# AS32x601 register map
File version: 1.0
CPU: RISC-V, little endian
Registers are 32-bit, read-write, reset 0x0 unless marked. A register's access mark holds for its fields unless they carry their own. Offsets are from the block's base; [hi:lo] are bit positions; {n}, {i} and the like mark numbered series.

## RTC — Real-Time Clock
Base 0x30101000
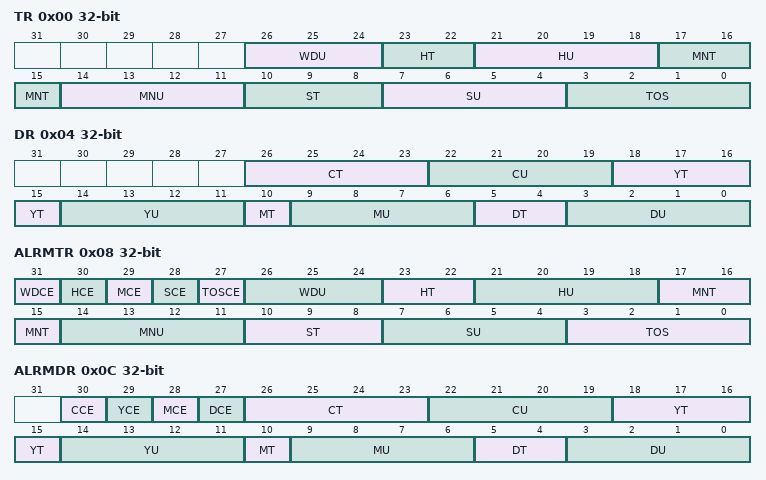
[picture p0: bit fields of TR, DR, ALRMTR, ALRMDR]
0x00 TR — RTC time register
  [26:24] WDU — Week day units [2:0]
  [23:22] HT — Hour tens [1:0]
  [21:18] HU — Hour units [3:0]
  [17:15] MNT — Minute tens [2:0]
  [14:11] MNU — Minute units [3:0]
  [10:8] ST — Second tens [2:0]
  [7:4] SU — Second units [3:0]
  [3:0] TOS — Tenth of a second [3:0]
0x04 DR — RTC date register
  [26:23] CT — Century tens [3:0]
  [22:19] CU — Century units [3:0]
  [18:15] YT — Year tens [3:0]
  [14:11] YU — Year units [3:0]
  [10] MT — Month tens
  [9:6] MU — Month units [3:0]
  [5:4] DT — Date tens [1:0]
  [3:0] DU — Date units [3:0]
0x08 ALRMTR — RTC alarm time register
  [31] WDCE — Week day comparison enable
  [30] HCE — Hour comparison enable
  [29] MCE — Minute comparison enable
  [28] SCE — Second comparison enable
  [27] TOSCE — One tenth of a second comparison enable
  [26:24] WDU — Week day units [2:0]
  [23:22] HT — Hour tens [1:0]
  [21:18] HU — Hour units [3:0]
  [17:15] MNT — Minute tens [2:0]
  [14:11] MNU — Minute units [3:0]
  [10:8] ST — Second tens [2:0]
  [7:4] SU — Second units [3:0]
  [3:0] TOS — Tenth of a second [3:0]
0x0C ALRMDR — RTC alarm date register
  [30] CCE — Century comparison enable
  [29] YCE — Year comparison enable
  [28] MCE — Month comparison enable
  [27] DCE — Date comparison enable
  [26:23] CT — Century tens [3:0]
  [22:19] CU — Century units [3:0]
  [18:15] YT — Year tens [3:0]
  [14:11] YU — Year units [3:0]
  [10] MT — Month tens
  [9:6] MU — Month units [3:0]
  [5:4] DT — Date tens [1:0]
  [3:0] DU — Date units [3:0]
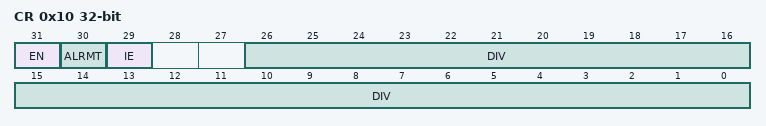
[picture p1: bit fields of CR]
0x10 CR — RTC control register
  [31] EN — RTC enable
  [30] ALRMT — Alarm trigger
  [29] IE — Interrupt enable
  [26:0] DIV — RTC clock divider [26:0]
0x14 WUCR — RTC wake-up control register
  [0] WUTE — Wakeup timer enable

## DAC0 — Digital-to-Analog Converter 0
Base 0x41003000
Same registers: DAC1 0x42002000
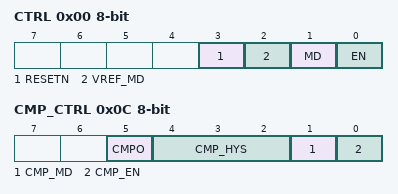
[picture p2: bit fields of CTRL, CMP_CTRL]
0x00 CTRL 8-bit — DAC Control Register
  [3] RESETN — DAC reset
  [2] VREF_MD — DAC VREF mode
  [1] MD — DAC mode
  [0] EN — DAC enable
0x04 DOUT 8-bit — DAC Data Register
  [7:0] DOUT — DAC output data [7:0]
0x08 CLK_DIV 8-bit — DAC Clock Division Register
  [7:0] CLK_DIV_NU — Clock division numerator [7:0]
0x0C CMP_CTRL 8-bit — DAC Comparator Control Register
  [5] CMPO — DAC comparator output
  [4:2] CMP_HYS — DAC comparator hysteresis [2:0]
  [1] CMP_MD — DAC comparator mode
  [0] CMP_EN — DAC comparator enable

## PKA — Public Key Accelerator
Base 0x41140000
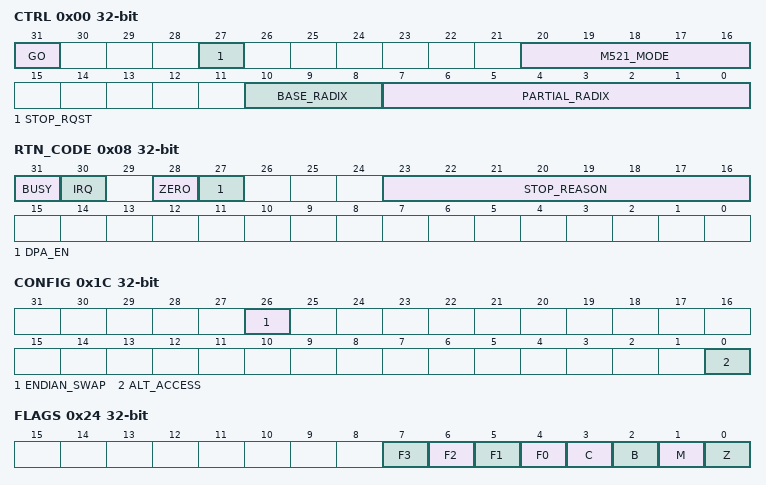
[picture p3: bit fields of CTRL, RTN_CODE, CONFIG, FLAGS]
0x00 CTRL — PKA Control Register
  [31] GO — Starts the PKA execution
  [27] STOP_RQST — Requests PKA to halt at the next instruction boundary
  [20:16] M521_MODE — Sets operating to Mersenne M-521
  [10:8] BASE_RADIX — Sets the size of the base operand size (radix)
  [7:0] PARTIAL_RADIX — Selects a partial field from within the base radix
0x04 ENTRY_PNT — PKA Program Entry Point Register
  [11:0] ADDR — Program entry point
0x08 RTN_CODE ro — PKA Return Code Register
  [31] BUSY — Indicates that the PKA is actively executing a program
  [30] IRQ — Indicates when the PKA has completed its task
  [28] ZERO — Indicates the state of the zero flag in the sequencer
  [27] DPA_EN — Indicates that the core is capable of operating in TA and/or DPA mode.
  [23:16] STOP_REASON — Indicates why the PKA stopped
0x14 INSTR_SINCE_GO — PKA Instructions Since GO Register
  [31:0] INSTRS — Number of instructions executed since the last GO command
0x1C CONFIG — Sets Configuration State Within The PKA
  [26] ENDIAN_SWAP — Cause the data memory regions to be endian swapped on transfer in or out of core
  [0] ALT_ACCESS — Enable the alternate access mode
0x20 STAT — PKA Status Register
  [30] DONE — Indicates that the operation has completed
0x24 FLAGS — PKA Flags Register
  [n+4] F{n} (n=0..3) — User flag {n}
  [3] C — Carry flag
  [2] B — Borrow flag
  [1] M — Memory-test flag
  [0] Z — Zero flag
0x28 WATCHDOG — PKA Watchdog Register
  [31:0] RELOAD — Reload value for the watchdog timer
0x2C CYCLES_SINCE_GO — PKA Cycles Since GO Register
  [31:0] CYCLES — Number of cycles since the last GO command
0x40 IRQ_EN — PKA Interrupt Enable Register
  [30] IE — Enable interrupt on PKA done

## TRNG — True Random Number Generator
Base 0x41150000
0x00 CTRL — TRNG Control Register
  [3:0] CMD — TRNG Execute A Command
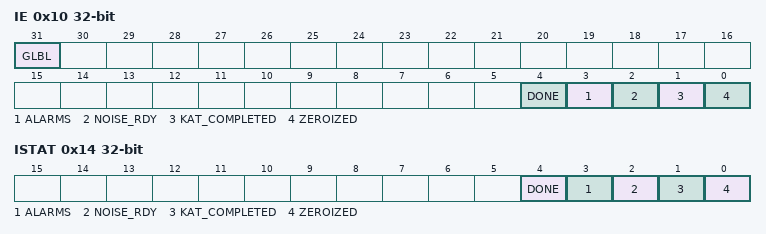
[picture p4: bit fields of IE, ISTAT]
0x10 IE — TRNG Interrupt Enable Register
  [31] GLBL — TRNG Global Interrupt Enable
  [4] DONE — TRNG Done Interrupt Enable
  [3] ALARMS — TRNG Alarms Interrupt Enable
  [2] NOISE_RDY — TRNG Noise Ready Interrupt Enable
  [1] KAT_COMPLETED — TRNG KAT Completed Interrupt Enable
  [0] ZEROIZED — TRNG Zeroized Interrupt Enable
0x14 ISTAT — TRNG Interrupt Status Register
  [4] DONE — TRNG Done Interrupt Status
  [3] ALARMS — TRNG Alarms Interrupt Status
  [2] NOISE_RDY — TRNG Noise Ready Interrupt Status
  [1] KAT_COMPLETED — TRNG KAT Completed Interrupt Status
  [0] ZEROIZED — TRNG Zeroized Interrupt Status
{0x24+4i} RAND{i} ro (i=0..3) — TRNG Random Number Register {i}
  [31:0] RAND — TRNG Random Number
